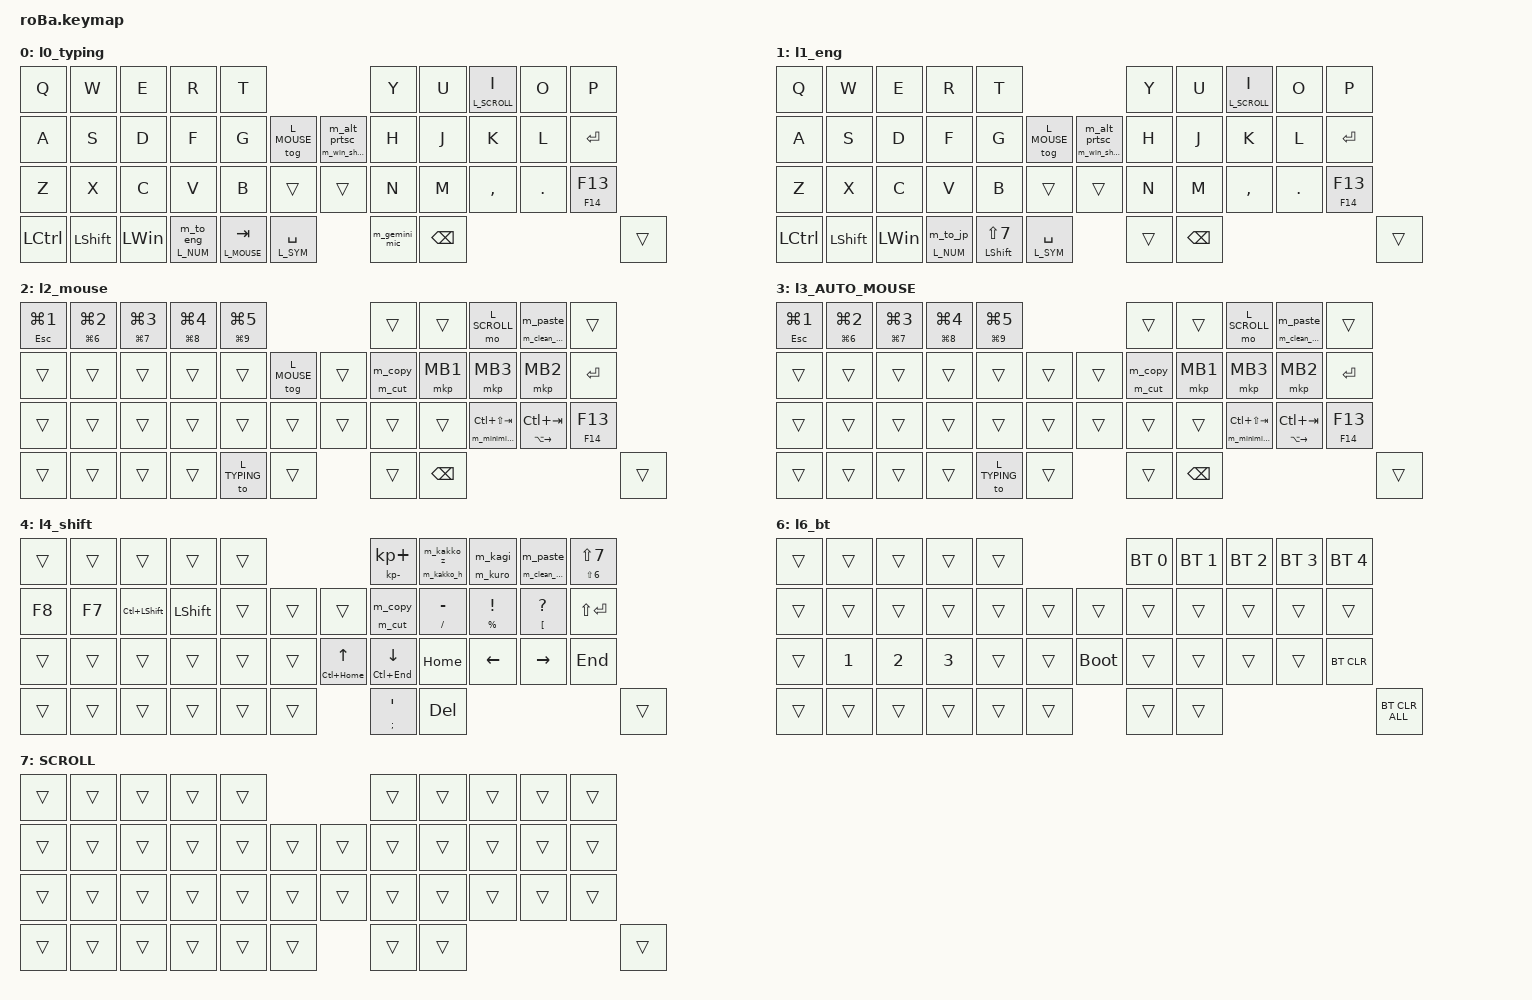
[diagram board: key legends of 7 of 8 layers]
#include <behaviors.dtsi>
#include <dt-bindings/zmk/bt.h>
#include <dt-bindings/zmk/keys.h>
#include <dt-bindings/zmk/pointing.h>

// --- レイヤー定義 ---
#define L_TYPING 0
#define L_ENG    1
#define L_MOUSE  2
#define L_AUTO   3
#define L_SYM    4
#define L_NUM    5
#define L_BT     6
#define L_SCROLL 7

&mt {
    flavor = "balanced";
    quick-tap-ms = <0>;
};

&trackball {
    automouse-layer = <L_AUTO>;
    scroll-layers = <L_SCROLL>;
};

/ {
    macros {
        m_minimize: m_minimize {
            compatible = "zmk,behavior-macro";
            #binding-cells = <0>;
            bindings = 
                <&macro_press &kp LALT>, 
                <&macro_tap &kp SPACE>, 
                <&macro_release &kp LALT>, 
                <&macro_wait_time 50>, 
                <&macro_tap &kp N>;
        };
        m_to_layer0: m_to_layer0 {
            compatible = "zmk,behavior-macro";
            #binding-cells = <0>;
            bindings = <&to L_TYPING>;
        };
        m_gemini_mic: m_gemini_mic {
            compatible = "zmk,behavior-macro";
            #binding-cells = <0>;
            bindings = <&kp LG(N1)>, <&macro_wait_time 200>, <&kp LA(D)>, <&macro_wait_time 100>, <&kp LS(TAB)>, <&kp LS(TAB)>, <&kp LS(TAB)>, <&kp ENTER>;
        };
        m_alt_prtsc: m_alt_prtsc {
            compatible = "zmk,behavior-macro";
            #binding-cells = <0>;
            bindings = <&kp LA(PRINTSCREEN)>;
        };
        m_win_shift_s: m_win_shift_s {
            compatible = "zmk,behavior-macro";
            #binding-cells = <0>;
            bindings = <&kp LG(LS(S))>;
        };
        m_up_arrow: m_up_arrow {
            compatible = "zmk,behavior-macro";
            #binding-cells = <0>;
            bindings = <&kp UP_ARROW>;
        };
        m_down_arrow: m_down_arrow {
            compatible = "zmk,behavior-macro";
            #binding-cells = <0>;
            bindings = <&kp DOWN_ARROW>;
        };
        m_PgUp: m_PgUp {
            compatible = "zmk,behavior-macro";
            #binding-cells = <0>;
            bindings = <&kp PG_UP>;
        };
        m_haifun: m_haifun {
            compatible = "zmk,behavior-macro";
            #binding-cells = <0>;
            bindings = <&kp MINUS>;
        };
        m_underbar: m_underbar {
            compatible = "zmk,behavior-macro";
            #binding-cells = <0>;
            bindings = <&kp LS(NON_US_BACKSLASH)>;
        };
        m_Ctrl_A: m_Ctrl_A {
            compatible = "zmk,behavior-macro";
            #binding-cells = <0>;
            bindings = <&kp LC(A)>;
        };
        m_mkp_right: m_mkp_right {
            compatible = "zmk,behavior-macro";
            #binding-cells = <0>;
            bindings = <&mkp MB2>;
        };
        m_copy: m_copy {
            compatible = "zmk,behavior-macro";
            #binding-cells = <0>;
            bindings = <&macro_press &kp LCTRL>, <&macro_tap &kp C>, <&macro_release &kp LCTRL>;
        };
        m_cut: m_cut {
            compatible = "zmk,behavior-macro";
            #binding-cells = <0>;
            bindings = <&macro_press &kp LCTRL>, <&macro_tap &kp X>, <&macro_release &kp LCTRL>;
        };
        m_paste: m_paste {
            compatible = "zmk,behavior-macro";
            #binding-cells = <0>;
            bindings = <&macro_press &kp LCTRL>, <&macro_tap &kp V>, <&macro_release &kp LCTRL>;
        };
        m_clean_paste: m_clean_paste {
            compatible = "zmk,behavior-macro";
            #binding-cells = <0>;
            bindings = <&macro_press &kp LCTRL &kp LSHIFT>, <&macro_tap &kp V>, <&macro_release &kp LCTRL &kp LSHIFT>;
        };

        m_kagi: m_kagi {
            compatible = "zmk,behavior-macro";
            #binding-cells = <0>;
            wait-ms = <30>;
            tap-ms = <30>;
            bindings = <&kp RBKT>, <&kp NON_US_HASH>, <&kp ENTER>, <&kp LEFT>;
        };
        m_kuro: m_kuro {
            compatible = "zmk,behavior-macro";
            #binding-cells = <0>;
            wait-ms = <30>;
            tap-ms = <30>;
            bindings = <&kp RBKT>, <&kp NON_US_HASH>, <&kp SPACE>, <&kp ENTER>, <&kp LEFT>;
        };
        m_kakko_z: m_kakko_z {
            compatible = "zmk,behavior-macro";
            #binding-cells = <0>;
            wait-ms = <30>;
            tap-ms = <30>;
            bindings = <&kp LS(N8)>, <&kp LS(N9)>, <&kp F9>, <&kp ENTER>, <&kp LEFT>;
        };
        m_kakko_h: m_kakko_h {
            compatible = "zmk,behavior-macro";
            #binding-cells = <0>;
            wait-ms = <30>;
            tap-ms = <30>;
            bindings = <&kp LS(N8)>, <&kp LS(N9)>, <&kp F10>, <&kp ENTER>, <&kp LEFT>;
        };

        m_to_eng: m_to_eng {
            compatible = "zmk,behavior-macro";
            #binding-cells = <0>;
            bindings = <&kp GRAVE>, <&to L_ENG>;
        };
        m_to_jp: m_to_jp {
            compatible = "zmk,behavior-macro";
            #binding-cells = <0>;
            bindings = <&kp GRAVE>, <&to L_TYPING>;
        };
    };

    behaviors {
        b_num_eng: b_num_eng {
            compatible = "zmk,behavior-hold-tap";
            bindings = <&mo>, <&m_to_eng>;
            #binding-cells = <2>;
            tapping-term-ms = <200>;
            flavor = "tap-preferred";
        };
        b_num_jp: b_num_jp {
            compatible = "zmk,behavior-hold-tap";
            bindings = <&mo>, <&m_to_jp>;
            #binding-cells = <2>;
            tapping-term-ms = <200>;
            flavor = "tap-preferred";
        };
        b_to_eng: b_to_eng {
            compatible = "zmk,behavior-hold-tap";
            bindings = <&mo>, <&m_to_eng>;
            #binding-cells = <2>;
            tapping-term-ms = <200>;
            flavor = "tap-preferred";
        };
        b_to_jp: b_to_jp {
            compatible = "zmk,behavior-hold-tap";
            bindings = <&mo>, <&m_to_jp>;
            #binding-cells = <2>;
            tapping-term-ms = <200>;
            flavor = "tap-preferred";
        };

        lt_to: lt_to {
            compatible = "zmk,behavior-hold-tap";
            bindings = <&mo>, <&to>;
            #binding-cells = <2>;
            tapping-term-ms = <200>;
            flavor = "tap-preferred";
        };
        lt_fast: lt_fast {
            compatible = "zmk,behavior-hold-tap";
            bindings = <&mo>, <&kp>;
            #binding-cells = <2>;
            tapping-term-ms = <130>;
            flavor = "tap-preferred";
        };
        b_min_tab: b_min_tab {
            compatible = "zmk,behavior-hold-tap";
            bindings = <&m_minimize>, <&kp>;
            #binding-cells = <2>;
            tapping-term-ms = <250>;
            flavor = "tap-preferred";
            quick-tap-ms = <0>;
        };
        b_ht: b_ht {
            compatible = "zmk,behavior-hold-tap";
            bindings = <&kp>, <&kp>;
            #binding-cells = <2>;
            tapping-term-ms = <250>;
            flavor = "tap-preferred";
            quick-tap-ms = <0>;
        };
        b_copy_cut: b_copy_cut {
            compatible = "zmk,behavior-hold-tap";
            bindings = <&m_cut>, <&m_copy>;
            #binding-cells = <2>;
            tapping-term-ms = <250>;
            flavor = "tap-preferred";
            quick-tap-ms = <0>;
        };
        b_paste_ht: b_paste_ht {
            compatible = "zmk,behavior-hold-tap";
            bindings = <&m_clean_paste>, <&m_paste>;
            #binding-cells = <2>;
            tapping-term-ms = <250>;
            flavor = "tap-preferred";
            quick-tap-ms = <0>;
        };
        lt_to_layer_0: lt_to_layer_0 {
            compatible = "zmk,behavior-hold-tap";
            bindings = <&mo>, <&m_to_layer0>;
            #binding-cells = <2>;
            tapping-term-ms = <200>;
            flavor = "tap-preferred";
        };
        b_scshot: b_scshot {
            compatible = "zmk,behavior-hold-tap";
            bindings = <&m_win_shift_s>, <&m_alt_prtsc>;
            #binding-cells = <2>; 
            tapping-term-ms = <150>;
            flavor = "tap-preferred";
        };
        b_UpArrow_PgUp: b_UpArrow_PgUp {
            compatible = "zmk,behavior-hold-tap";
            bindings = <&m_PgUp>, <&m_up_arrow>;
            #binding-cells = <2>;
            tapping-term-ms = <200>;
            flavor = "tap-preferred";
        };
        b_haifun_underbar: b_haifun_underbar {
            compatible = "zmk,behavior-hold-tap";
            bindings = <&m_underbar>, <&m_haifun>;
            #binding-cells = <2>;
            tapping-term-ms = <200>;
            flavor = "tap-preferred";
        };
        b_AltTab: b_AltTab {
            compatible = "zmk,behavior-hold-tap";
            bindings = <&kp>, <&kp>;
            #binding-cells = <2>;
            tapping-term-ms = <150>;
            flavor = "tap-preferred";
        };
        b_CtrlW_CtrlShiftT: b_CtrlW_CtrlShiftT {
            compatible = "zmk,behavior-hold-tap";
            bindings = <&kp>, <&kp>;
            #binding-cells = <2>;
            tapping-term-ms = <200>;
            flavor = "tap-preferred";
        };
        b_kagi: b_kagi {
            compatible = "zmk,behavior-hold-tap";
            bindings = <&m_kuro>, <&m_kagi>;
            #binding-cells = <2>;
            tapping-term-ms = <250>;
            flavor = "tap-preferred";
        };
        b_kakko: b_kakko {
            compatible = "zmk,behavior-hold-tap";
            bindings = <&m_kakko_h>, <&m_kakko_z>;
            #binding-cells = <2>;
            tapping-term-ms = <250>;
            flavor = "tap-preferred";
        };
    };

    combos {
        compatible = "zmk,combos";
        tab { bindings = <&kp TAB>; key-positions = <11 12>; };
        shift_tab { bindings = <&kp LS(TAB)>; key-positions = <12 13>; };
        double_quotation { bindings = <&kp DOUBLE_QUOTES>; key-positions = <20 21>; };
        eq { bindings = <&kp EQUAL>; key-positions = <24 25>; };
    };

    keymap {
        compatible = "zmk,keymap";

        l0_typing {
            bindings = <
&kp Q      &kp W         &kp E         &kp R            &kp T                                              &kp Y          &kp U  &lt L_SCROLL I    &kp O    &kp P
&kp A      &kp S         &kp D         &kp F            &kp G        &tog L_MOUSE       &b_scshot 0 0      &kp H          &kp J  &kp K             &kp L    &kp ENTER
&kp Z      &kp X         &kp C         &kp V            &kp B        &trans             &trans             &kp N          &kp M  &kp COMMA         &kp DOT  &b_ht F14 F13
&kp LCTRL  &kp LSHIFT    &kp LEFT_WIN  &b_num_eng L_NUM 0  &lt L_MOUSE TAB  &lt_fast L_SYM SPACE           &m_gemini_mic  &kp BACKSPACE                                     &trans
            >;
            sensor-bindings = <&inc_dec_kp PG_UP PAGE_DOWN>;
        };

        l1_eng {
            bindings = <
&kp Q      &kp W         &kp E         &kp R            &kp T                                              &kp Y          &kp U  &lt L_SCROLL I    &kp O    &kp P
&kp A      &kp S         &kp D         &kp F            &kp G        &tog L_MOUSE       &b_scshot 0 0      &kp H          &kp J  &kp K             &kp L    &kp ENTER
&kp Z      &kp X         &kp C         &kp V            &kp B        &trans             &trans             &kp N          &kp M  &kp COMMA         &kp DOT  &b_ht F14 F13
&kp LCTRL  &kp LSHIFT    &kp LEFT_WIN  &b_num_jp L_NUM 0   &mt LSHIFT LS(N7)   &lt_fast L_SYM SPACE          &trans         &kp BACKSPACE                                     &trans
            >;
            sensor-bindings = <&inc_dec_kp PG_UP PAGE_DOWN>;
        };

        l2_mouse {
            bindings = <
&b_ht ESC LG(N1)  &b_ht LG(N6) LG(N2)  &b_ht LG(N7) LG(N3)  &b_ht LG(N8) LG(N4)  &b_ht LG(N9) LG(N5)      &trans  &trans  &mo L_SCROLL       &b_paste_ht 0 0              &trans
&trans            &trans               &trans               &trans               &trans                   &tog L_MOUSE    &trans  &b_copy_cut 0 0    &mkp MB1                     &mkp MB3                     &mkp MB2                 &kp ENTER
&trans            &trans               &trans               &trans               &trans                   &trans  &trans  &trans             &trans                       &b_min_tab 0 LC(LS(TAB))     &b_ht LA(RIGHT) LC(TAB)  &b_ht F14 F13
&trans            &trans               &trans               &trans               &to L_TYPING             &trans  &trans  &kp BACKSPACE                                                                                             &trans
            >;
            sensor-bindings = <&inc_dec_kp 0 0>;
        };

        l3_AUTO_MOUSE {
            bindings = <
&b_ht ESC LG(N1)  &b_ht LG(N6) LG(N2)  &b_ht LG(N7) LG(N3)  &b_ht LG(N8) LG(N4)  &b_ht LG(N9) LG(N5)      &trans  &trans  &mo L_SCROLL       &b_paste_ht 0 0              &trans
&trans            &trans               &trans               &trans               &trans                   &trans  &trans  &b_copy_cut 0 0    &mkp MB1                     &mkp MB3                     &mkp MB2                 &kp ENTER
&trans            &trans               &trans               &trans               &trans                   &trans  &trans  &trans             &trans                       &b_min_tab 0 LC(LS(TAB))     &b_ht LA(RIGHT) LC(TAB)  &b_ht F14 F13
&trans            &trans               &trans               &trans               &to L_TYPING             &trans  &trans  &kp BACKSPACE                                                                                             &trans
            >;
            sensor-bindings = <&inc_dec_kp 0 0>;
        };

        l4_shift {
            bindings = <
&trans  &trans  &trans          &trans      &trans                                           &b_ht KP_MINUS KP_PLUS    &b_kakko 0 0      &b_kagi 0 0       &b_paste_ht 0 0   &b_ht LS(N6) LS(N7)
&kp F8  &kp F7  &kp LC(LSHIFT)  &kp LSHIFT  &trans  &trans  &trans        &b_copy_cut 0 0    &b_ht FSLH MINUS          &b_ht PRCNT EXCL  &b_ht LBKT QMARK  &kp LS(ENTER)
&trans  &trans  &trans          &trans      &trans  &trans  &b_ht LC(HOME) UP_ARROW  &b_ht LC(END) DOWN_ARROW  &kp HOME          &kp LEFT_ARROW    &kp RIGHT_ARROW   &kp END
&trans  &trans  &trans          &trans      &trans  &trans  &b_ht SEMI SQT           &kp DELETE                &trans
            >;
        };

        l5_number {
            bindings = <
&trans  &trans     &trans        &trans       &trans                                 &trans     &kp N1  &kp N2  &kp N3  &kp LS(MINUS)
&trans  &kp MINUS  &kp LS(SEMI)  &kp EQUAL    &trans         &trans  &kp MINUS       &kp N4     &kp N5  &kp N6  &kp N0
&trans  &kp FSLH   &kp LS(SQT)   &trans       &trans         &trans  &kp DOT         &kp N7     &kp N8  &kp N9  &trans
&trans  &trans     &trans        &trans       &trans         &trans  &trans                                     &trans
            >;
        };

        l6_bt {
            bindings = <
&trans  &trans  &trans  &trans  &trans                            &bt BT_SEL 0  &bt BT_SEL 1  &bt BT_SEL 2  &bt BT_SEL 3  &bt BT_SEL 4
&trans  &trans  &trans  &trans  &trans  &trans      &trans        &trans        &trans        &trans        &trans        &trans
&trans  &kp N1  &kp N2  &kp N3  &trans  &trans      &bootloader   &trans        &trans        &trans        &trans        &bt BT_CLR
&trans  &trans  &trans  &trans  &trans  &trans      &trans        &trans                                                  &bt BT_CLR_ALL
            >;
        };

        SCROLL {
            bindings = <
&trans  &trans  &trans  &trans  &trans                      &trans  &trans  &trans  &trans  &trans
&trans  &trans  &trans  &trans  &trans  &trans      &trans  &trans  &trans  &trans  &trans  &trans
&trans  &trans  &trans  &trans  &trans  &trans      &trans  &trans  &trans  &trans  &trans  &trans
&trans  &trans  &trans  &trans  &trans  &trans      &trans  &trans                          &trans
            >;
        };
    };
};
